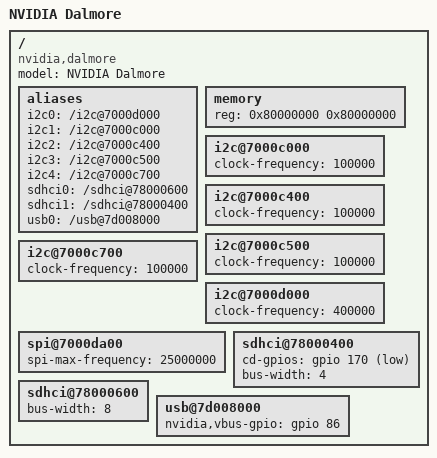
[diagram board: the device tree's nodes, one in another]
/dts-v1/;

#include "tegra114.dtsi"

/ {
	model = "NVIDIA Dalmore";
	compatible = "nvidia,dalmore", "nvidia,tegra114";

	aliases {
		i2c0 = "/i2c@7000d000";
		i2c1 = "/i2c@7000c000";
		i2c2 = "/i2c@7000c400";
		i2c3 = "/i2c@7000c500";
		i2c4 = "/i2c@7000c700";
		sdhci0 = "/sdhci@78000600";
		sdhci1 = "/sdhci@78000400";
		usb0 = "/usb@7d008000";
	};

	memory {
		device_type = "memory";
		reg = <0x80000000 0x80000000>;
	};

	i2c@7000c000 {
		status = "okay";
		clock-frequency = <100000>;
	};

	i2c@7000c400 {
		status = "okay";
		clock-frequency = <100000>;
	};

	i2c@7000c500 {
		status = "okay";
		clock-frequency = <100000>;
	};

	i2c@7000c700 {
		status = "okay";
		clock-frequency = <100000>;
	};

	i2c@7000d000 {
		status = "okay";
		clock-frequency = <400000>;
	};

	spi@7000da00 {
		status = "okay";
		spi-max-frequency = <25000000>;
	};

	sdhci@78000400 {
		cd-gpios = <&gpio 170 1>; /* gpio PV2 */
		bus-width = <4>;
		status = "okay";
	};

	sdhci@78000600 {
		bus-width = <8>;
		status = "okay";
	};

	usb@7d008000 {
		/* SPDIF_IN: USB_VBUS_EN1 */
		nvidia,vbus-gpio = <&gpio 86 0>;
		status = "okay";
	};
};
